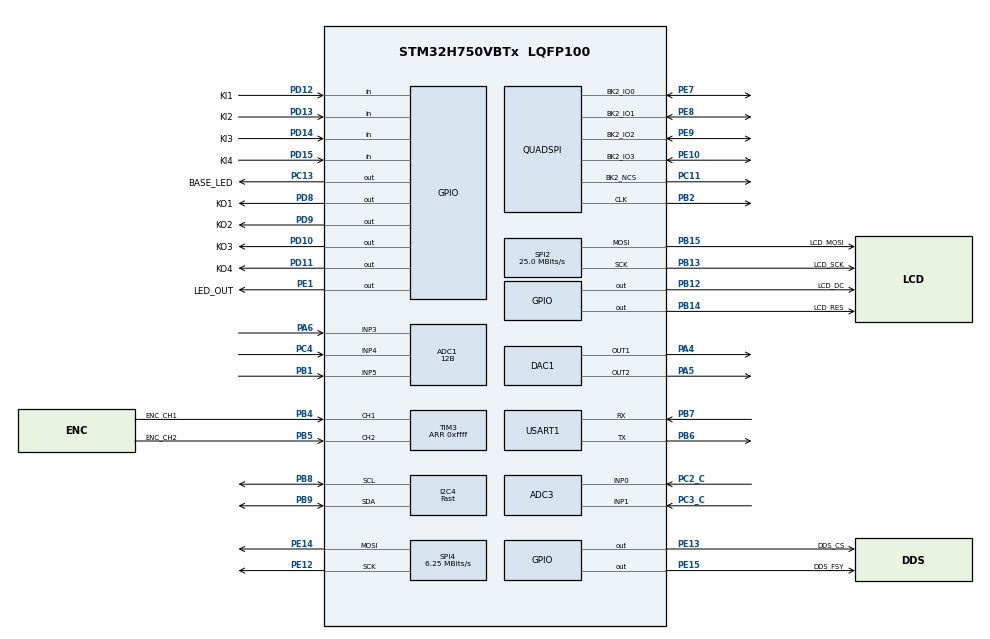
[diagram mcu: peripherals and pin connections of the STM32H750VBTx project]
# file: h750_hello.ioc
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ADC1.Channel-0\#ChannelRegularConversion=ADC_CHANNEL_3
ADC1.Channel-3\#ChannelRegularConversion=ADC_CHANNEL_4
ADC1.Channel-4\#ChannelRegularConversion=ADC_CHANNEL_5
ADC1.ClockPrescaler=ADC_CLOCK_ASYNC_DIV2
ADC1.ContinuousConvMode=DISABLE
ADC1.ConversionDataManagement=ADC_CONVERSIONDATA_DMA_CIRCULAR
ADC1.ExternalTrigConv=ADC_EXTERNALTRIG_T2_TRGO
ADC1.NbrOfConversion=3
ADC1.NbrOfConversionFlag=1
ADC1.OffsetNumber-0\#ChannelRegularConversion=ADC_OFFSET_NONE
ADC1.OffsetNumber-3\#ChannelRegularConversion=ADC_OFFSET_NONE
ADC1.OffsetNumber-4\#ChannelRegularConversion=ADC_OFFSET_NONE
ADC1.Overrun=ADC_OVR_DATA_OVERWRITTEN
ADC1.OversamplingMode=DISABLE
ADC1.Rank-0\#ChannelRegularConversion=1
ADC1.Rank-3\#ChannelRegularConversion=2
ADC1.Rank-4\#ChannelRegularConversion=3
ADC1.Resolution=ADC_RESOLUTION_12B
ADC1.SamplingTime-0\#ChannelRegularConversion=ADC_SAMPLETIME_2CYCLES_5
ADC1.SamplingTime-3\#ChannelRegularConversion=ADC_SAMPLETIME_2CYCLES_5
ADC1.SamplingTime-4\#ChannelRegularConversion=ADC_SAMPLETIME_2CYCLES_5
ADC1.master=1
ADC3.Channel-0\#ChannelRegularConversion=ADC_CHANNEL_0
ADC3.Channel-1\#ChannelRegularConversion=ADC_CHANNEL_1
ADC3.ConversionDataManagement=ADC_CONVERSIONDATA_DMA_CIRCULAR
ADC3.ExternalTrigConv=ADC_EXTERNALTRIG_T8_TRGO
ADC3.NbrOfConversion=2
ADC3.NbrOfConversionFlag=1
ADC3.OffsetNumber-0\#ChannelRegularConversion=ADC_OFFSET_NONE
ADC3.OffsetNumber-1\#ChannelRegularConversion=ADC_OFFSET_NONE
ADC3.Rank-0\#ChannelRegularConversion=1
ADC3.Rank-1\#ChannelRegularConversion=2
ADC3.SamplingTime-0\#ChannelRegularConversion=ADC_SAMPLETIME_64CYCLES_5
ADC3.SamplingTime-1\#ChannelRegularConversion=ADC_SAMPLETIME_64CYCLES_5
CORTEX_M7.CPU_DCache=Enabled
CORTEX_M7.CPU_ICache=Enabled
DAC1.DAC_Channel-DAC_OUT2=DAC_CHANNEL_2
DAC1.DAC_Trigger-DAC_OUT1=DAC_TRIGGER_T15_TRGO
DAC1.DAC_Trigger-DAC_OUT2=DAC_TRIGGER_T15_TRGO
DAC1.DAC_UserTrimming-DAC_OUT1=DAC_TRIMMING_FACTORY
Dma.ADC1.1.Direction=DMA_PERIPH_TO_MEMORY
Dma.ADC1.1.EventEnable=DISABLE
Dma.ADC1.1.FIFOMode=DMA_FIFOMODE_DISABLE
Dma.ADC1.1.Instance=DMA1_Stream1
Dma.ADC1.1.MemDataAlignment=DMA_MDATAALIGN_HALFWORD
Dma.ADC1.1.MemInc=DMA_MINC_ENABLE
Dma.ADC1.1.Mode=DMA_CIRCULAR
Dma.ADC1.1.PeriphDataAlignment=DMA_PDATAALIGN_HALFWORD
Dma.ADC1.1.PeriphInc=DMA_PINC_DISABLE
Dma.ADC1.1.Polarity=HAL_DMAMUX_REQ_GEN_RISING
Dma.ADC1.1.Priority=DMA_PRIORITY_VERY_HIGH
Dma.ADC1.1.RequestNumber=1
Dma.ADC1.1.SignalID=NONE
Dma.ADC1.1.SyncEnable=DISABLE
Dma.ADC1.1.SyncPolarity=HAL_DMAMUX_SYNC_NO_EVENT
Dma.ADC1.1.SyncRequestNumber=1
Dma.ADC1.1.SyncSignalID=NONE
Dma.ADC3.5.Direction=DMA_PERIPH_TO_MEMORY
Dma.ADC3.5.EventEnable=DISABLE
Dma.ADC3.5.FIFOMode=DMA_FIFOMODE_DISABLE
Dma.ADC3.5.Instance=DMA1_Stream7
Dma.ADC3.5.MemDataAlignment=DMA_MDATAALIGN_HALFWORD
Dma.ADC3.5.MemInc=DMA_MINC_ENABLE
Dma.ADC3.5.Mode=DMA_CIRCULAR
Dma.ADC3.5.PeriphDataAlignment=DMA_PDATAALIGN_HALFWORD
Dma.ADC3.5.PeriphInc=DMA_PINC_DISABLE
Dma.ADC3.5.Polarity=HAL_DMAMUX_REQ_GEN_RISING
Dma.ADC3.5.Priority=DMA_PRIORITY_MEDIUM
Dma.ADC3.5.RequestNumber=1
Dma.ADC3.5.SignalID=NONE
Dma.ADC3.5.SyncEnable=DISABLE
Dma.ADC3.5.SyncPolarity=HAL_DMAMUX_SYNC_NO_EVENT
Dma.ADC3.5.SyncRequestNumber=1
Dma.ADC3.5.SyncSignalID=NONE
Dma.DAC1_CH1.0.Direction=DMA_MEMORY_TO_PERIPH
Dma.DAC1_CH1.0.EventEnable=DISABLE
Dma.DAC1_CH1.0.FIFOMode=DMA_FIFOMODE_DISABLE
Dma.DAC1_CH1.0.Instance=DMA1_Stream4
Dma.DAC1_CH1.0.MemDataAlignment=DMA_MDATAALIGN_HALFWORD
Dma.DAC1_CH1.0.MemInc=DMA_MINC_ENABLE
Dma.DAC1_CH1.0.Mode=DMA_NORMAL
Dma.DAC1_CH1.0.PeriphDataAlignment=DMA_PDATAALIGN_HALFWORD
Dma.DAC1_CH1.0.PeriphInc=DMA_PINC_DISABLE
Dma.DAC1_CH1.0.Polarity=HAL_DMAMUX_REQ_GEN_RISING
Dma.DAC1_CH1.0.Priority=DMA_PRIORITY_VERY_HIGH
Dma.DAC1_CH1.0.RequestNumber=1
Dma.DAC1_CH1.0.SignalID=NONE
Dma.DAC1_CH1.0.SyncEnable=DISABLE
Dma.DAC1_CH1.0.SyncPolarity=HAL_DMAMUX_SYNC_NO_EVENT
Dma.DAC1_CH1.0.SyncRequestNumber=1
Dma.DAC1_CH1.0.SyncSignalID=NONE
Dma.DAC1_CH2.4.Direction=DMA_MEMORY_TO_PERIPH
Dma.DAC1_CH2.4.EventEnable=DISABLE
Dma.DAC1_CH2.4.FIFOMode=DMA_FIFOMODE_DISABLE
Dma.DAC1_CH2.4.Instance=DMA1_Stream3
Dma.DAC1_CH2.4.MemDataAlignment=DMA_MDATAALIGN_HALFWORD
Dma.DAC1_CH2.4.MemInc=DMA_MINC_ENABLE
Dma.DAC1_CH2.4.Mode=DMA_NORMAL
Dma.DAC1_CH2.4.PeriphDataAlignment=DMA_PDATAALIGN_HALFWORD
Dma.DAC1_CH2.4.PeriphInc=DMA_PINC_DISABLE
Dma.DAC1_CH2.4.Polarity=HAL_DMAMUX_REQ_GEN_RISING
Dma.DAC1_CH2.4.Priority=DMA_PRIORITY_VERY_HIGH
Dma.DAC1_CH2.4.RequestNumber=1
Dma.DAC1_CH2.4.SignalID=NONE
Dma.DAC1_CH2.4.SyncEnable=DISABLE
Dma.DAC1_CH2.4.SyncPolarity=HAL_DMAMUX_SYNC_NO_EVENT
Dma.DAC1_CH2.4.SyncRequestNumber=1
Dma.DAC1_CH2.4.SyncSignalID=NONE
Dma.Request0=DAC1_CH1
Dma.Request1=ADC1
Dma.Request2=SPI2_TX
Dma.Request3=TIM4_UP
Dma.Request4=DAC1_CH2
Dma.Request5=ADC3
Dma.SPI2_TX.2.Direction=DMA_MEMORY_TO_PERIPH
Dma.SPI2_TX.2.EventEnable=DISABLE
Dma.SPI2_TX.2.FIFOMode=DMA_FIFOMODE_DISABLE
Dma.SPI2_TX.2.Instance=DMA1_Stream0
Dma.SPI2_TX.2.MemDataAlignment=DMA_MDATAALIGN_BYTE
Dma.SPI2_TX.2.MemInc=DMA_MINC_ENABLE
Dma.SPI2_TX.2.Mode=DMA_NORMAL
Dma.SPI2_TX.2.PeriphDataAlignment=DMA_PDATAALIGN_BYTE
Dma.SPI2_TX.2.PeriphInc=DMA_PINC_DISABLE
Dma.SPI2_TX.2.Polarity=HAL_DMAMUX_REQ_GEN_RISING
Dma.SPI2_TX.2.Priority=DMA_PRIORITY_HIGH
Dma.SPI2_TX.2.RequestNumber=1
Dma.SPI2_TX.2.SignalID=NONE
Dma.SPI2_TX.2.SyncEnable=DISABLE
Dma.SPI2_TX.2.SyncPolarity=HAL_DMAMUX_SYNC_NO_EVENT
Dma.SPI2_TX.2.SyncRequestNumber=1
Dma.SPI2_TX.2.SyncSignalID=NONE
Dma.TIM4_UP.3.Direction=DMA_MEMORY_TO_PERIPH
Dma.TIM4_UP.3.EventEnable=DISABLE
Dma.TIM4_UP.3.FIFOMode=DMA_FIFOMODE_DISABLE
Dma.TIM4_UP.3.Instance=DMA1_Stream5
Dma.TIM4_UP.3.MemDataAlignment=DMA_MDATAALIGN_HALFWORD
Dma.TIM4_UP.3.MemInc=DMA_MINC_ENABLE
Dma.TIM4_UP.3.Mode=DMA_CIRCULAR
Dma.TIM4_UP.3.PeriphDataAlignment=DMA_PDATAALIGN_HALFWORD
Dma.TIM4_UP.3.PeriphInc=DMA_PINC_DISABLE
Dma.TIM4_UP.3.Polarity=HAL_DMAMUX_REQ_GEN_RISING
Dma.TIM4_UP.3.Priority=DMA_PRIORITY_HIGH
Dma.TIM4_UP.3.RequestNumber=1
Dma.TIM4_UP.3.SignalID=NONE
Dma.TIM4_UP.3.SyncEnable=DISABLE
Dma.TIM4_UP.3.SyncPolarity=HAL_DMAMUX_SYNC_NO_EVENT
Dma.TIM4_UP.3.SyncRequestNumber=1
Dma.TIM4_UP.3.SyncSignalID=NONE
I2C4.Analog_Filter=I2C_ANALOGFILTER_DISABLE
I2C4.I2C_Fall_Time=0
I2C4.I2C_Rise_Time=0
I2C4.I2C_Speed_Mode=I2C_Fast
I2C4.Speed=400
I2C4.Timing=0x009039BB
Mcu.Family=STM32H7
Mcu.Name=STM32H750VBTx
Mcu.Package=LQFP100
Mcu.UserConstants=HT_PERIOD,8000;H_CMP,2000
NVIC.ADC_IRQn=true\:0\:0\:false\:false\:true\:true\:true
NVIC.DMA1_Stream0_IRQn=true\:0\:0\:false\:false\:true\:false\:true
NVIC.DMA1_Stream1_IRQn=true\:0\:0\:false\:false\:true\:false\:true
NVIC.DMA1_Stream3_IRQn=true\:0\:0\:false\:false\:true\:false\:true
NVIC.DMA1_Stream4_IRQn=true\:0\:0\:false\:false\:true\:false\:true
NVIC.DMA1_Stream5_IRQn=true\:0\:0\:false\:false\:true\:false\:true
NVIC.DMA1_Stream7_IRQn=true\:0\:0\:false\:false\:true\:false\:true
NVIC.I2C4_ER_IRQn=true\:0\:0\:false\:false\:true\:true\:true
NVIC.I2C4_EV_IRQn=true\:0\:0\:false\:false\:true\:true\:true
NVIC.PriorityGroup=NVIC_PRIORITYGROUP_4
NVIC.SPI2_IRQn=true\:0\:0\:false\:false\:true\:false\:true
PA13\ (JTMS/SWDIO).Mode=Serial_Wire
PA13\ (JTMS/SWDIO).Signal=DEBUG_JTMS-SWDIO
PA14\ (JTCK/SWCLK).Mode=Serial_Wire
PA14\ (JTCK/SWCLK).Signal=DEBUG_JTCK-SWCLK
PA4.Signal=COMP_DAC11_group
PA5.Signal=COMP_DAC12_group
PA6.Signal=ADCx_INP3
PB1.Signal=ADCx_INP5
PB12.GPIO_Label=LCD_DC
PB12.GPIO_PuPd=GPIO_PULLUP
PB12.GPIO_Speed=GPIO_SPEED_FREQ_VERY_HIGH
PB12.Signal=GPIO_Output
PB13.GPIO_Label=LCD_SCK
PB13.GPIO_Speed=GPIO_SPEED_FREQ_VERY_HIGH
PB13.Mode=TX_Only_Simplex_Unidirect_Master
PB13.Signal=SPI2_SCK
PB14.GPIO_Label=LCD_RES
PB14.GPIO_Speed=GPIO_SPEED_FREQ_VERY_HIGH
PB14.Signal=GPIO_Output
PB15.GPIO_Label=LCD_MOSI
PB15.GPIO_Speed=GPIO_SPEED_FREQ_VERY_HIGH
PB15.Mode=TX_Only_Simplex_Unidirect_Master
PB15.Signal=SPI2_MOSI
PB2.GPIO_Speed=GPIO_SPEED_FREQ_VERY_HIGH
PB2.Mode=Single Bank 2
PB2.Signal=QUADSPI_CLK
PB4\ (NJTRST).GPIO_Label=ENC_CH1
PB4\ (NJTRST).GPIO_PuPd=GPIO_PULLUP
PB4\ (NJTRST).Signal=S_TIM3_CH1
PB5.GPIO_Label=ENC_CH2
PB5.GPIO_PuPd=GPIO_PULLUP
PB5.Signal=S_TIM3_CH2
PB6.Mode=Asynchronous
PB6.Signal=USART1_TX
PB7.Mode=Asynchronous
PB7.Signal=USART1_RX
PB8.Mode=I2C
PB8.Signal=I2C4_SCL
PB9.Mode=I2C
PB9.Signal=I2C4_SDA
PC11.GPIO_Speed=GPIO_SPEED_FREQ_VERY_HIGH
PC11.Mode=Single Bank 2
PC11.Signal=QUADSPI_BK2_NCS
PC13.GPIO_Label=BASE_LED
PC13.Signal=GPIO_Output
PC2_C.Mode=IN0-Single-Ended
PC2_C.Signal=ADC3_INP0
PC3_C.Mode=IN1-Single-Ended
PC3_C.Signal=ADC3_INP1
PC4.Signal=ADCx_INP4
PD10.GPIO_Label=KO3
PD10.GPIO_PuPd=GPIO_PULLUP
PD10.PinState=GPIO_PIN_SET
PD10.Signal=GPIO_Output
PD11.GPIO_Label=KO4
PD11.GPIO_PuPd=GPIO_PULLUP
PD11.PinState=GPIO_PIN_SET
PD11.Signal=GPIO_Output
PD12.GPIO_Label=KI1
PD12.GPIO_PuPd=GPIO_PULLUP
PD12.Signal=GPIO_Input
PD13.GPIO_Label=KI2
PD13.GPIO_PuPd=GPIO_PULLUP
PD13.Signal=GPIO_Input
PD14.GPIO_Label=KI3
PD14.GPIO_PuPd=GPIO_PULLUP
PD14.Signal=GPIO_Input
PD15.GPIO_Label=KI4
PD15.GPIO_PuPd=GPIO_PULLUP
PD15.Signal=GPIO_Input
PD8.GPIO_Label=KO1
PD8.GPIO_PuPd=GPIO_PULLUP
PD8.PinState=GPIO_PIN_SET
PD8.Signal=GPIO_Output
PD9.GPIO_Label=KO2
PD9.GPIO_PuPd=GPIO_PULLUP
PD9.PinState=GPIO_PIN_SET
PD9.Signal=GPIO_Output
PE1.GPIO_Label=LED_OUT
PE1.GPIO_Speed=GPIO_SPEED_FREQ_HIGH
PE1.PinState=GPIO_PIN_SET
PE1.Signal=GPIO_Output
PE10.GPIO_Speed=GPIO_SPEED_FREQ_VERY_HIGH
PE10.Mode=Single Bank 2
PE10.Signal=QUADSPI_BK2_IO3
PE12.GPIO_Speed=GPIO_SPEED_FREQ_VERY_HIGH
PE12.Mode=TX_Only_Simplex_Unidirect_Master
PE12.Signal=SPI4_SCK
PE13.GPIO_Label=DDS_CS
PE13.GPIO_Speed=GPIO_SPEED_FREQ_LOW
PE13.PinState=GPIO_PIN_SET
PE13.Signal=GPIO_Output
PE14.GPIO_Speed=GPIO_SPEED_FREQ_VERY_HIGH
PE14.Mode=TX_Only_Simplex_Unidirect_Master
PE14.Signal=SPI4_MOSI
PE15.GPIO_Label=DDS_FSY
PE15.GPIO_Speed=GPIO_SPEED_FREQ_LOW
PE15.PinState=GPIO_PIN_SET
PE15.Signal=GPIO_Output
PE7.GPIO_Speed=GPIO_SPEED_FREQ_VERY_HIGH
PE7.Mode=Single Bank 2
PE7.Signal=QUADSPI_BK2_IO0
PE8.GPIO_Speed=GPIO_SPEED_FREQ_VERY_HIGH
PE8.Mode=Single Bank 2
PE8.Signal=QUADSPI_BK2_IO1
PE9.GPIO_Speed=GPIO_SPEED_FREQ_VERY_HIGH
PE9.Mode=Single Bank 2
PE9.Signal=QUADSPI_BK2_IO2
PH0-OSC_IN\ (PH0).Mode=HSE-External-Oscillator
PH0-OSC_IN\ (PH0).Signal=RCC_OSC_IN
PH1-OSC_OUT\ (PH1).Mode=HSE-External-Oscillator
PH1-OSC_OUT\ (PH1).Signal=RCC_OSC_OUT
ProjectManager.HeapSize=0x600
ProjectManager.StackSize=0xa00
ProjectManager.TargetToolchain=MDK-ARM V5
QUADSPI.ChipSelectHighTime=QSPI_CS_HIGH_TIME_1_CYCLE
QUADSPI.ClockPrescaler=2-1
QUADSPI.FifoThreshold=4
QUADSPI.FlashSize=22
QUADSPI.SampleShifting=QSPI_SAMPLE_SHIFTING_HALFCYCLE
RCC.ADCCLockSelection=RCC_ADCCLKSOURCE_CLKP
RCC.ADCFreq_Value=64000000
RCC.APB1Freq_Value=100000000
RCC.APB2Freq_Value=100000000
RCC.APB3Freq_Value=100000000
RCC.APB4Freq_Value=100000000
RCC.CortexFreq_Value=400000000
RCC.D1PPRE=RCC_APB3_DIV2
RCC.D2PPRE1=RCC_APB1_DIV2
RCC.D2PPRE2=RCC_APB2_DIV2
RCC.D3PPRE=RCC_APB4_DIV2
RCC.DIVM1=4
RCC.DIVM2=8
RCC.DIVM3=8
RCC.DIVN1=400
RCC.DIVN2=400
RCC.DIVN3=200
RCC.EXTERNAL_CLOCK_VALUE=12288000
RCC.HCLKFreq_Value=200000000
RCC.HPRE=RCC_HCLK_DIV2
RCC.HRTIMCLockSelection=RCC_HRTIM1CLK_CPUCLK
RCC.HSE_VALUE=8000000
RCC.PLL2FRACN=0
RCC.PLL3FRACN=0
RCC.PLLFRACN=0
RCC.PLLSourceVirtual=RCC_PLLSOURCE_HSE
RCC.PWR_Regulator_Voltage_Scale=PWR_REGULATOR_VOLTAGE_SCALE1
RCC.SYSCLKFreq_VALUE=400000000
RCC.SYSCLKSource=RCC_SYSCLKSOURCE_PLLCLK
RCC.USBFreq_Value=400000000
SH.ADCx_INP3.0=ADC1_INP3,IN3-Single-Ended
SH.ADCx_INP4.0=ADC1_INP4,IN4-Single-Ended
SH.ADCx_INP5.0=ADC1_INP5,IN5-Single-Ended
SH.COMP_DAC11_group.0=DAC1_OUT1,DAC_OUT1
SH.COMP_DAC12_group.0=DAC1_OUT2,DAC_OUT2
SH.S_TIM3_CH1.0=TIM3_CH1,Encoder_Interface
SH.S_TIM3_CH2.0=TIM3_CH2,Encoder_Interface
SPI2.BaudRatePrescaler=SPI_BAUDRATEPRESCALER_16
SPI2.CLKPhase=SPI_PHASE_2EDGE
SPI2.CLKPolarity=SPI_POLARITY_HIGH
SPI2.CalculateBaudRate=25.0 MBits/s
SPI2.DataSize=SPI_DATASIZE_8BIT
SPI2.Direction=SPI_DIRECTION_2LINES_TXONLY
SPI2.Mode=SPI_MODE_MASTER
SPI2.VirtualType=VM_MASTER
SPI4.BaudRatePrescaler=SPI_BAUDRATEPRESCALER_16
SPI4.CLKPolarity=SPI_POLARITY_HIGH
SPI4.CalculateBaudRate=6.25 MBits/s
SPI4.DataSize=SPI_DATASIZE_8BIT
SPI4.Direction=SPI_DIRECTION_2LINES_TXONLY
SPI4.Mode=SPI_MODE_MASTER
SPI4.VirtualType=VM_MASTER
SYS.PVDLevel=PWR_PVDLEVEL_3
TIM15.AutoReloadPreload=TIM_AUTORELOAD_PRELOAD_ENABLE
TIM15.Period=25000
TIM15.Prescaler=0
TIM15.TIM_MasterOutputTrigger=TIM_TRGO_UPDATE
TIM2.Period=200
TIM2.TIM_MasterOutputTrigger=TIM_TRGO_UPDATE
TIM3.AutoReloadPreload=TIM_AUTORELOAD_PRELOAD_DISABLE
TIM3.EncoderMode=TIM_ENCODERMODE_TI12
TIM3.IC1Filter=6
TIM3.IC1Polarity=TIM_ICPOLARITY_FALLING
TIM3.IC2Filter=6
TIM3.IC2Polarity=TIM_ICPOLARITY_FALLING
TIM3.Period=0xffff
TIM4.AutoReloadPreload=TIM_AUTORELOAD_PRELOAD_ENABLE
TIM4.Period=(4535)-1
TIM4.TIM_MasterOutputTrigger=TIM_TRGO_UPDATE
TIM5.TIM_MasterOutputTrigger=TIM_TRGO_UPDATE
TIM8.AutoReloadPreload=TIM_AUTORELOAD_PRELOAD_ENABLE
TIM8.Period=100-1
TIM8.Prescaler=200-1
TIM8.TIM_MasterOutputTrigger=TIM_TRGO_UPDATE
USART1.VirtualMode-Asynchronous=VM_ASYNC
VP_PWR_V_VREFBUF.Mode=ExternalMode
VP_TIM15_VS_ClockSourceINT.Mode=Internal
VP_TIM2_VS_ClockSourceINT.Mode=Internal
VP_TIM4_VS_ClockSourceINT.Mode=Internal
VP_TIM5_VS_ClockSourceINT.Mode=Internal
VP_TIM8_VS_ClockSourceINT.Mode=Internal
board=custom

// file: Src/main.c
/* USER CODE BEGIN Header */
/**
  ******************************************************************************
  * @file           : main.c
  * @brief          : Main program body
  ******************************************************************************
  ** This notice applies to any and all portions of this file
  * that are not between comment pairs USER CODE BEGIN and
  * USER CODE END. Other portions of this file, whether
  * inserted by the user or by software development tools
  * are owned by their respective copyright owners.
  *
  * COPYRIGHT(c) 2019 STMicroelectronics
  *
  * Redistribution and use in source and binary forms, with or without modification,
  * are permitted provided that the following conditions are met:
  *   1. Redistributions of source code must retain the above copyright notice,
  *      this list of conditions and the following disclaimer.
  *   2. Redistributions in binary form must reproduce the above copyright notice,
  *      this list of conditions and the following disclaimer in the documentation
  *      and/or other materials provided with the distribution.
  *   3. Neither the name of STMicroelectronics nor the names of its contributors
  *      may be used to endorse or promote products derived from this software
  *      without specific prior written permission.
  *
  * THIS SOFTWARE IS PROVIDED BY THE COPYRIGHT HOLDERS AND CONTRIBUTORS "AS IS"
  * AND ANY EXPRESS OR IMPLIED WARRANTIES, INCLUDING, BUT NOT LIMITED TO, THE
  * IMPLIED WARRANTIES OF MERCHANTABILITY AND FITNESS FOR A PARTICULAR PURPOSE ARE
  * DISCLAIMED. IN NO EVENT SHALL THE COPYRIGHT HOLDER OR CONTRIBUTORS BE LIABLE
  * FOR ANY DIRECT, INDIRECT, INCIDENTAL, SPECIAL, EXEMPLARY, OR CONSEQUENTIAL
  * DAMAGES (INCLUDING, BUT NOT LIMITED TO, PROCUREMENT OF SUBSTITUTE GOODS OR
  * SERVICES; LOSS OF USE, DATA, OR PROFITS; OR BUSINESS INTERRUPTION) HOWEVER
  * CAUSED AND ON ANY THEORY OF LIABILITY, WHETHER IN CONTRACT, STRICT LIABILITY,
  * OR TORT (INCLUDING NEGLIGENCE OR OTHERWISE) ARISING IN ANY WAY OUT OF THE USE
  * OF THIS SOFTWARE, EVEN IF ADVISED OF THE POSSIBILITY OF SUCH DAMAGE.
  *
  ******************************************************************************
  */
/* USER CODE END Header */

#include "main.h"
#include "adc.h"
#include "dac.h"
#include "dma.h"
#include "i2c.h"
#include "quadspi.h"
#include "spi.h"
#include "tim.h"
#include "usart.h"
#include "gpio.h"

/* USER CODE BEGIN Includes */
#include "user_main.h"
/* USER CODE END Includes */

void SystemClock_Config(void);

int main(void)
{

  /* Enable I-Cache---------------------------------------------------------*/
  SCB_EnableICache();

  /* Enable D-Cache---------------------------------------------------------*/
  SCB_EnableDCache();

  /* MCU Configuration--------------------------------------------------------*/

  /* Reset of all peripherals, Initializes the Flash interface and the Systick. */
  HAL_Init();

  /* USER CODE BEGIN Init */
  /**Supply configuration update enable
  */
  MODIFY_REG(PWR->CR3, PWR_CR3_SCUEN, 0);

  /* USER CODE END Init */

  /* Configure the system clock */
  SystemClock_Config();

  /* Initialize all configured peripherals */
  MX_GPIO_Init();
  MX_DMA_Init();
  MX_USART1_UART_Init();
  MX_QUADSPI_Init();
  MX_DAC1_Init();
  MX_ADC1_Init();
  MX_TIM3_Init();
  MX_SPI2_Init();
  MX_TIM15_Init();
  MX_TIM4_Init();
  MX_TIM2_Init();
  MX_SPI4_Init();
  MX_ADC3_Init();
  MX_TIM5_Init();
  MX_TIM8_Init();
  MX_I2C4_Init();
  /* USER CODE BEGIN 2 */
  user_setup();
  /* USER CODE END 2 */

  /* Infinite loop */
  /* USER CODE BEGIN WHILE */
  while (1)
  {
    user_loop();
    /* USER CODE END WHILE */

  }
}

void SystemClock_Config(void)
{
  RCC_OscInitTypeDef RCC_OscInitStruct = {0};
  RCC_ClkInitTypeDef RCC_ClkInitStruct = {0};
  RCC_PeriphCLKInitTypeDef PeriphClkInitStruct = {0};

  /** Supply configuration update enable
  */
  HAL_PWREx_ConfigSupply(PWR_LDO_SUPPLY);
  /** Configure the main internal regulator output voltage
  */
  __HAL_PWR_VOLTAGESCALING_CONFIG(PWR_REGULATOR_VOLTAGE_SCALE1);

  while(!__HAL_PWR_GET_FLAG(PWR_FLAG_VOSRDY)) {}
  /** Initializes the CPU, AHB and APB busses clocks
  */
  RCC_OscInitStruct.OscillatorType = RCC_OSCILLATORTYPE_HSI|RCC_OSCILLATORTYPE_HSE;
  RCC_OscInitStruct.HSEState = RCC_HSE_ON;
  RCC_OscInitStruct.HSIState = RCC_HSI_DIV1;
  RCC_OscInitStruct.HSICalibrationValue = RCC_HSICALIBRATION_DEFAULT;
  RCC_OscInitStruct.PLL.PLLState = RCC_PLL_ON;
  RCC_OscInitStruct.PLL.PLLSource = RCC_PLLSOURCE_HSE;
  RCC_OscInitStruct.PLL.PLLM = 4;
  RCC_OscInitStruct.PLL.PLLN = 400;
  RCC_OscInitStruct.PLL.PLLP = 2;
  RCC_OscInitStruct.PLL.PLLQ = 2;
  RCC_OscInitStruct.PLL.PLLR = 2;
  RCC_OscInitStruct.PLL.PLLRGE = RCC_PLL1VCIRANGE_1;
  RCC_OscInitStruct.PLL.PLLVCOSEL = RCC_PLL1VCOWIDE;
  RCC_OscInitStruct.PLL.PLLFRACN = 0;
  if (HAL_RCC_OscConfig(&RCC_OscInitStruct) != HAL_OK)
  {
    Error_Handler();
  }
  /** Initializes the CPU, AHB and APB busses clocks
  */
  RCC_ClkInitStruct.ClockType = RCC_CLOCKTYPE_HCLK|RCC_CLOCKTYPE_SYSCLK
                              |RCC_CLOCKTYPE_PCLK1|RCC_CLOCKTYPE_PCLK2
                              |RCC_CLOCKTYPE_D3PCLK1|RCC_CLOCKTYPE_D1PCLK1;
  RCC_ClkInitStruct.SYSCLKSource = RCC_SYSCLKSOURCE_PLLCLK;
  RCC_ClkInitStruct.SYSCLKDivider = RCC_SYSCLK_DIV1;
  RCC_ClkInitStruct.AHBCLKDivider = RCC_HCLK_DIV2;
  RCC_ClkInitStruct.APB3CLKDivider = RCC_APB3_DIV2;
  RCC_ClkInitStruct.APB1CLKDivider = RCC_APB1_DIV2;
  RCC_ClkInitStruct.APB2CLKDivider = RCC_APB2_DIV2;
  RCC_ClkInitStruct.APB4CLKDivider = RCC_APB4_DIV2;

  if (HAL_RCC_ClockConfig(&RCC_ClkInitStruct, FLASH_LATENCY_2) != HAL_OK)
  {
    Error_Handler();
  }
  PeriphClkInitStruct.PeriphClockSelection = RCC_PERIPHCLK_USART1|RCC_PERIPHCLK_SPI4
                              |RCC_PERIPHCLK_SPI2|RCC_PERIPHCLK_ADC
                              |RCC_PERIPHCLK_I2C4|RCC_PERIPHCLK_QSPI
                              |RCC_PERIPHCLK_CKPER;
  PeriphClkInitStruct.QspiClockSelection = RCC_QSPICLKSOURCE_D1HCLK;
  PeriphClkInitStruct.CkperClockSelection = RCC_CLKPSOURCE_HSI;
  PeriphClkInitStruct.Spi123ClockSelection = RCC_SPI123CLKSOURCE_PLL;
  PeriphClkInitStruct.Spi45ClockSelection = RCC_SPI45CLKSOURCE_D2PCLK1;
  PeriphClkInitStruct.Usart16ClockSelection = RCC_USART16CLKSOURCE_D2PCLK2;
  PeriphClkInitStruct.I2c4ClockSelection = RCC_I2C4CLKSOURCE_D3PCLK1;
  PeriphClkInitStruct.AdcClockSelection = RCC_ADCCLKSOURCE_CLKP;
  if (HAL_RCCEx_PeriphCLKConfig(&PeriphClkInitStruct) != HAL_OK)
  {
    Error_Handler();
  }
}

void Error_Handler(void)
{
  /* USER CODE BEGIN Error_Handler_Debug */
  /* User can add his own implementation to report the HAL error return state */
  APP_ERROR("Error_Handler\r\n");
  /* USER CODE END Error_Handler_Debug */
}

#ifdef  USE_FULL_ASSERT
/**
  * @brief  Reports the name of the source file and the source line number
  *         where the assert_param error has occurred.
  * @param  file: pointer to the source file name
  * @param  line: assert_param error line source number
  * @retval None
  */
void assert_failed(uint8_t *file, uint32_t line)
{
  /* USER CODE BEGIN 6 */
  APP_ERROR("assert_failed %s (%d)\r\n", file, line);
  /* User can add his own implementation to report the file name and line number,
     tex: printf("Wrong parameters value: file %s on line %d\r\n", file, line) */
  /* USER CODE END 6 */
}
#endif /* USE_FULL_ASSERT */

/************************ (C) COPYRIGHT STMicroelectronics *****END OF FILE****/
